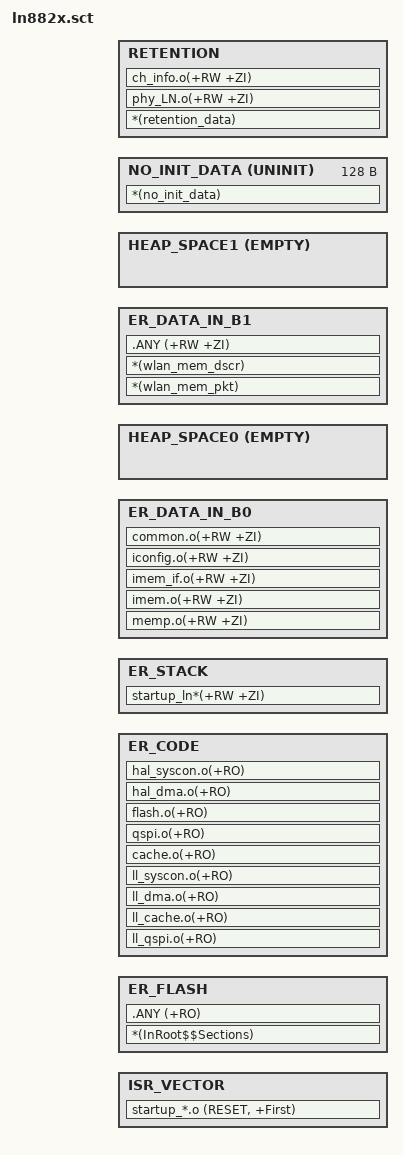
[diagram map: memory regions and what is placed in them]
#! armcc -E
#include "flash_partition_table.h"
#include ".\..\..\..\..\platform\vendor_bsp\LN\ln882x\include\cpu\ARM_CM4F\ln88xx\mem_map_ln882x.h"


LR_FLASH CACHE_FLASH_BASE+APP_SPACE_OFFSET+IMAGE_HEADER_SIZE APP_SPACE_SIZE
{; load region size_region

    ISR_VECTOR RAM_BASE ALIGN 0x100
    {
        startup_*.o (RESET, +First)
    }

    ER_FLASH CACHE_FLASH_BASE+APP_SPACE_OFFSET+IMAGE_HEADER_SIZE + ImageLength(ISR_VECTOR) APP_SPACE_SIZE
    {; load address = execution address
        *(InRoot$$Sections)
        .ANY (+RO)
    }

    ER_CODE ImageLimit(ISR_VECTOR)
    {
        ;mandatory item
        ll_qspi.o(+RO)
        ll_cache.o(+RO)
        ll_dma.o(+RO)
        ll_syscon.o(+RO)
        ;ll_sleep.o(+RO)
        ;ll_rtc.o(+RO)
        cache.o(+RO)
        qspi.o(+RO)
        flash.o(+RO)
        hal_dma.o(+RO)
        hal_syscon.o(+RO)
        ;hal_sleep.o(+RO)
        ;hal_rtc.o(+RO)
        ;port.o(XIR)

        ;optional item
        ;ll_uart.o(+RO)
        ;hal_uart.o(+RO)
        ;log.o(+RO)
        ;serial.o(+RO)
        ;serial_art2000.o(+RO)
        ;fifobuf.o(+RO)
    }

    ER_STACK +0
    {
        startup_ln*(+RW +ZI)
    }

    ER_DATA_IN_B0 +0 RAM_BLOCK0_SIZE-ImageLength(ISR_VECTOR)-ImageLength(ER_CODE)-ImageLength(ER_STACK)
    {
		memp.o(+RW +ZI)
		imem.o(+RW +ZI)
		imem_if.o(+RW +ZI)
		;cglobals_sta.o(+RW +ZI)
		;event_manager.o(+RW +ZI)
		iconfig.o(+RW +ZI)
		common.o(+RW +ZI)
    }

    HEAP_SPACE0 +0 EMPTY RAM_BLOCK1_BASE-ImageLimit(ER_DATA_IN_B0)
    {; Heap region
    }

	ER_DATA_IN_B1 RAM_BLOCK1_BASE RAM_BLOCK1_SIZE
    {
		*(wlan_mem_pkt)
		*(wlan_mem_dscr)
		.ANY (+RW +ZI)
    }

    ;IQ Data area cannot be used by ER_DATA region
    ;ScatterAssert(ImageLimit(ER_DATA) < (0x20020300))

    HEAP_SPACE1 +0 EMPTY RETENTION_MEM_BASE-ImageLimit(ER_DATA_IN_B1)
    {; Heap region
    }

    NO_INIT_DATA RETENTION_MEM_BASE  UNINIT 0x80
    {
        *(no_init_data)
    }

    RETENTION RETENTION_MEM_BASE+0x80 ANY_SIZE 0x2000-0x80-16 RETENTION_MEM_SIZE
    {
        *(retention_data)
        phy_LN.o(+RW +ZI)
        ch_info.o(+RW +ZI)
    }
}	
	

